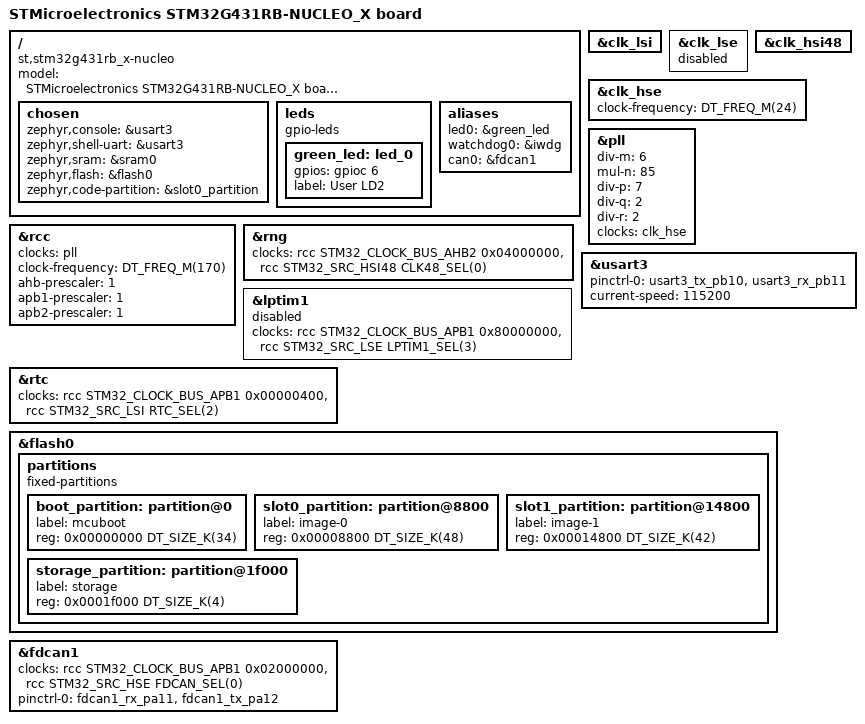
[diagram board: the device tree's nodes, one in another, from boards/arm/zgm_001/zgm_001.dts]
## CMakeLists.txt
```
# SPDX-License-Identifier: Apache-2.0

cmake_minimum_required(VERSION 3.20.0)

set(BOARD_ROOT ${CMAKE_CURRENT_SOURCE_DIR})
set(DTS_ROOT ${CMAKE_CURRENT_SOURCE_DIR})
set(DTC_OVERLAY_FILE ${CMAKE_CURRENT_SOURCE_DIR}/../modules/lib/motorlib/drivers/drivers@Eulre.0.1.overlay)

get_filename_component(MODULES_BASE_PATH "${CMAKE_CURRENT_SOURCE_DIR}/../modules/lib" ABSOLUTE)

# 添加Zephyr外部模块
list(APPEND ZEPHYR_EXTRA_MODULES
    "${MODULES_BASE_PATH}/motorlib"
    "${MODULES_BASE_PATH}/CommonLibrary"
    "${MODULES_BASE_PATH}/ProtocolV4"    
)


find_package(Zephyr REQUIRED HINTS $ENV{ZEPHYR_BASE})

project(euler)

# 添加源文件到 app target
target_sources(app PRIVATE
    src/main.c
    src/shell.c
)
```

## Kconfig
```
#motor / Kconfig
#必须包含 Zephyr 的主 Kconfig 以初始化核心配置
source "Kconfig.zephyr" 
```

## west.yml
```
manifest:
  self:
    path: Euler  # 修正拼写错误

  remotes:
    - name: github
      url-base: ssh://git@github.com 
    - name: origin 
      url-base: ssh://git@github.com/zagerx  # 改为 SSH 协议

  defaults:
    remote: origin
    revision: master
   
  projects:
    - name: zephyr
      remote: github
      repo-path: zephyrproject-rtos/zephyr
      revision: v4.1.0
      import: submanifests
      import:
        name-allowlist:
          - cmsis
          - cmsis-dsp
          - hal_stm32
          - segger
          - zcbor
          - canopennode
    - name: ProtocolV4
      path: modules/lib/ProtocolV4
      submodules: true
      revision: master

    - name: motorlib
      path: modules/lib/motorlib
      revision: master

    - name: CommonLibrary
      path: modules/lib/CommonLibrary
      revision: master

    - name: CustomMCUBoot
      path: bootloader/mcuboot
      remote: origin  # 改为存在的 remote
      revision: CustomMCUBoot

    - name: syrius-dts
      path: syrius-dts/
      remote: origin  # 改为存在的 remote
      revision: master
    
    - name: syrius-boards
      path: syrius-boards/
      remote: origin  # 改为存在的 remote
      revision: master
```

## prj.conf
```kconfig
CONFIG_GPIO=y
CONFIG_LOG=y
# 禁用 UART 控制台输出
CONFIG_UART_CONSOLE=y
CONFIG_UART_CONSOLE=y
CONFIG_SHELL=y
CONFIG_SHELL_BACKEND_SERIAL=y

# 启用 RTT 控制台
CONFIG_RTT_CONSOLE=n
CONFIG_TRACING=n
CONFIG_SEGGER_SYSTEMVIEW=n
CONFIG_USE_SEGGER_RTT=n

CONFIG_FPU=y
CONFIG_FPU_SHARING=y

#CONFIG_BOOTLOADER_MCUBOOT=y
#CONFIG_MCUBOOT_SIGNATURE_KEY_FILE="bootloader/mcuboot/root-rsa-2048.pem"
CONFIG_MOTORLIB_ENABLE=y
CONFIG_MOTOR_LIB_LOG_LEVEL=4
CONFIG_MOTOR_SUPER_ABZHALL_400W=n

CONFIG_ENCODER_TYPE_AS5047=y
CONFIG_SPI=y
CONFIG_USER_USE_STM32_HAL_SPI=y
CONFIG_USER_USE_STM32_HAL_ADC=y
CONFIG_USER_USE_STM32_HAL_TIM=y

CONFIG_MOTOR_DEBUG_MODE=y
CONFIG_MOTOR_DEBUG_ENCODERMODE=n
CONFIG_MOTOR_DEBUG_SELFLOOPMODE=y
CONFIG_MOTOR_DEBUG_TORQUE_PID=n
CONFIG_SPEEDLOOP_DEBUG=n
CONFIG_ABS_TYPE_ENCODER_CALIBRA=n
```

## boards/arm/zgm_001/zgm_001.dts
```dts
/*
 * Copyright (c) 2019 Richard Osterloh <richard.osterloh@gmail.com>
 *
 * SPDX-License-Identifier: Apache-2.0
 */

/dts-v1/;
#include <st/g4/stm32g431Xb.dtsi>
#include <st/g4/stm32g431c(6-8-b)ux-pinctrl.dtsi>

/ {
	model = "STMicroelectronics STM32G431RB-NUCLEO_X board";
	compatible = "st,stm32g431rb_x-nucleo";

	chosen {
		zephyr,console = &usart3;
		zephyr,shell-uart = &usart3;
		zephyr,sram = &sram0;
		zephyr,flash = &flash0;
		zephyr,code-partition = &slot0_partition;
	};

	leds: leds {
		compatible = "gpio-leds";
		green_led: led_0 {
			gpios = <&gpioc 6 GPIO_ACTIVE_HIGH>;
			label = "User LD2";
		};
	};
	aliases {
		led0 = &green_led;
		watchdog0 = &iwdg;
		can0 = &fdcan1;
	};
};

&clk_lsi {
	status = "okay";
};

&clk_lse {
	status = "disabled";
};

&clk_hsi48 {
	status = "okay";
};

&clk_hse {
	clock-frequency = <DT_FREQ_M(24)>;
	status = "okay";
};

&pll {
	div-m = <6>;
	mul-n = <85>;
	div-p = <7>;
	div-q = <2>;
	div-r = <2>;
	clocks = <&clk_hse>;
	status = "okay";
};

&rcc {
	clocks = <&pll>;
	clock-frequency = <DT_FREQ_M(170)>;
	ahb-prescaler = <1>;
	apb1-prescaler = <1>;
	apb2-prescaler = <1>;
};

&rng {
	clocks = <&rcc STM32_CLOCK_BUS_AHB2 0x04000000>,
		 <&rcc STM32_SRC_HSI48 CLK48_SEL(0)>;
	status = "okay";
};

&usart3 {
	pinctrl-0 = <&usart3_tx_pb10 &usart3_rx_pb11>;
	pinctrl-names = "default";
	current-speed = <115200>;
	status = "okay";
};

stm32_lp_tick_source: &lptim1 {
	clocks = <&rcc STM32_CLOCK_BUS_APB1 0x80000000>,
		 <&rcc STM32_SRC_LSE LPTIM1_SEL(3)>;
	status = "disabled";
};

&rtc {
	clocks = <&rcc STM32_CLOCK_BUS_APB1 0x00000400>,
		 <&rcc STM32_SRC_LSI RTC_SEL(2)>;
	status = "okay";
};

&flash0 {

	partitions {
		compatible = "fixed-partitions";
		#address-cells = <1>;
		#size-cells = <1>;

		boot_partition: partition@0 {
			label = "mcuboot";
			reg = <0x00000000 DT_SIZE_K(34)>;
		};
		slot0_partition: partition@8800 {
			label = "image-0";
			reg = <0x00008800 DT_SIZE_K(48)>;
		};
		slot1_partition: partition@14800 {
			label = "image-1";
			reg = <0x00014800 DT_SIZE_K(42)>;
		};
		/* Set 4Kb of storage at the end of the 128Kb of flash */
		storage_partition: partition@1f000 {
			label = "storage";
			reg = <0x0001f000 DT_SIZE_K(4)>;
		};
	};
};

/* 配置 CAN1 控制器 */
&fdcan1 {
	clocks = <&rcc STM32_CLOCK_BUS_APB1 0x02000000>,
	<&rcc STM32_SRC_HSE FDCAN_SEL(0)>;
	pinctrl-0 = <&fdcan1_rx_pa11 &fdcan1_tx_pa12>;
	pinctrl-names = "default";
	status = "okay";    
};
```

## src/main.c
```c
/*
 * Copyright (c) 2016 Intel Corporation
 *
 * SPDX-License-Identifier: Apache-2.0
 */

#include <zephyr/drivers/gpio.h>
#include <zephyr/kernel.h>
#include <zephyr/kernel.h>
#include "fault_monitoring_module.h"
#include "statemachine.h"
#include "zephyr/device.h"
#include <zephyr/drivers/gpio.h>
#include <zephyr/logging/log.h>
#include <lib/motor/motor.h>
#include <fault_monitoring_module.h>
#include <zephyr/sys/reboot.h>
/* 1000 msec = 1 sec */
#define LED0_NODE DT_ALIAS(led0)
const struct gpio_dt_spec led = GPIO_DT_SPEC_GET(LED0_NODE, gpios);

int main(void)
{
	const struct device *motor0 = DEVICE_DT_GET(DT_NODELABEL(motor0));
	const struct motor_data *m_data = motor0->data;
	gpio_pin_configure_dt(&led, GPIO_OUTPUT_ACTIVE); /* 先点亮 */

	int ret;
	// float bus_volcurur[2];
	// fmm_t *bus_vol_fmm = m_data->fault[0];
	// fmm_t *buf_curr_fmm = m_data->fault[1];
	// fmm_init(bus_vol_fmm, 60.0f, 48.0f, 5, 5, NULL);
	// fmm_init(buf_curr_fmm, 5.0f, 0.0f, 5, 5, NULL);

	// static int16_t fault_fsm = 0;
	static uint32_t conut = 0;
	k_msleep(200);
	while (1) {
		if (conut++ > 500) {
			conut = 0;
			gpio_pin_toggle_dt(&led);
		}
		// motor_get_bus_voltage_current(motor0, &bus_volcurur[0], &bus_volcurur[1]);
		// motor_set_vol(motor0, bus_volcurur);

		// fmm_monitoring(bus_vol_fmm, bus_volcurur[0]);
		// fmm_monitoring(buf_curr_fmm, bus_volcurur[1]);

		DISPATCH_FSM(m_data->mode_state_mec);

		k_msleep(1);
	}
	return ret;
}
```

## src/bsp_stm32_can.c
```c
#include <string.h>
#include <zephyr/device.h>
#include <zephyr/drivers/can.h>
#include <zephyr/kernel.h>
#include <zephyr/logging/log.h>
#include <zephyr/sys/printk.h>
LOG_MODULE_REGISTER(stm32_can, LOG_LEVEL_DBG);

const struct device *const can_dev = DEVICE_DT_GET(DT_NODELABEL(fdcan1));

// 前置声明
static void can_rx_callback(const struct device *dev, struct can_frame *frame, void *user_data);

int can_init(void)
{
	if (!device_is_ready(can_dev)) {
		LOG_INF("dev no ready");
		return -ENODEV;
	}
	// 停止 CAN 设备
	can_stop(can_dev);
	k_msleep(100); // 等待设备完全停止

	struct can_timing timing;
	int ret = can_calc_timing(can_dev, &timing, 1000000, 875); // 10kbps, 87.5%采样点
	if (ret < 0) {
		return ret;
	}

	ret = can_set_timing(can_dev, &timing);
	if (ret < 0) {
		return ret;
	}

	// 设置模式前确保控制器就绪
	while (can_set_mode(can_dev, CAN_MODE_NORMAL) == -EBUSY) {
		k_msleep(1);
	}

	// LOG_INF("can init finish");

	struct can_filter filter = {
		.id = 0x00000000,   // 匹配所有标准ID
		.mask = 0x00000000, // 掩码全0表示不检查任何位
		.flags = 0          // 明确指定标准帧
	};
	int filter_id = can_add_rx_filter(can_dev, can_rx_callback, NULL, &filter);
	LOG_INF("Added filter %d (id=0x%x mask=0x%x)", filter_id, filter.id, filter.mask);

	// 打印硬件状态
	uint32_t core_clock;
	can_get_core_clock(can_dev, &core_clock);
	LOG_INF("CAN core clock: %u Hz", core_clock);

	can_start(can_dev);
	return 0;
}
K_MSGQ_DEFINE(rx_msgq, sizeof(struct can_frame), 10, 4);

static void can_rx_callback(const struct device *dev, struct can_frame *frame, void *user_data)
{
	//   k_msgq_put(&rx_msgq, frame, K_NO_WAIT); // 非阻塞入队
	LOG_INF("RX ID:%03x DLC:%d Data:", frame->id, frame->dlc);
	for (int i = 0; i < frame->dlc; i++) {
		LOG_INF("%02x ", frame->data[i]);
	}
	LOG_INF("");
}
```

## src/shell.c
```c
#include <zephyr/kernel.h>
#include <zephyr/shell/shell.h>
#include <stdlib.h>
#include <zephyr/drivers/gpio.h>

#include "lib/motor/motor.h"
#include "zephyr/posix/sys/stat.h"
const struct device *motor = DEVICE_DT_GET(DT_NODELABEL(motor0));

static int cmd_hello(const struct shell *sh, size_t argc, char **argv)
{
	ARG_UNUSED(argc);
	ARG_UNUSED(argv);

	shell_print(sh, "Hello Zephyr Shell! argc=%d", argc);
	return 0;
}

static int cmd_motor_set_ready(const struct shell *sh, size_t argc, char **argv)
{
	ARG_UNUSED(argc);
	ARG_UNUSED(argv);
	motor_set_state(motor, MOTOR_STATE_READY);
	return 0;
}
// static int cmd_motor_set_aligh(const struct shell *sh, size_t argc, char **argv)
// {
// 	ARG_UNUSED(argc);
// 	ARG_UNUSED(argv);
// 	motor_set_state(motor, MOTOR_STATE_ALIGN);
// 	return 0;
// }
static int cmd_motor_set_disable(const struct shell *sh, size_t argc, char **argv)
{
	ARG_UNUSED(argc);
	ARG_UNUSED(argv);
	motor_set_state(motor, MOTOR_STATE_STOP);
	return 0;
}
static int cmd_motor_set_closeloop(const struct shell *sh, size_t argc, char **argv)
{
	ARG_UNUSED(argc);
	ARG_UNUSED(argv);
	motor_set_state(motor, MOTOR_STATE_CLOSED_LOOP);
	return 0;
}
static int cmd_motor_set_speed(const struct shell *sh, size_t argc, char **argv)
{
	if (argc != 2) {
		shell_error(sh, "Usage: add <num1> <num2>");
		return -EINVAL;
	}
	long temp = strtol(argv[1], NULL, 0);
	float speed = (float)temp / 1000.0f;
	motor_set_target_speed(motor, speed);
	motor_set_state(motor, MOTOR_STATE_CLOSED_LOOP);
	return 0;
}

static int cmd_motor_set_mode(const struct shell *sh, size_t argc, char **argv)
{
	if (argc != 2) {
		shell_error(sh, "Usage: add <num1> <num2>");
		return -EINVAL;
	}
	long mode = strtol(argv[1], NULL, 0);
	if (mode == 1) {
		motor_set_mode(motor, MOTOR_MODE_SPEED);
	} else if (mode == 2) {
		motor_set_mode(motor, MOTOR_MODE_POSI);
	} else if (mode == 3) {
		motor_set_mode(motor, MOTOR_MODE_TORQUE);
	} else if (mode == 5) {
		motor_set_mode(motor, MOTOR_MODE_IDLE);
	}
	return 0;
}
static int cmd_motor_set_toque(const struct shell *sh, size_t argc, char **argv)
{
	if (argc != 3) {
		shell_error(sh, "Usage: add <num1> <num2>");
		return -EINVAL;
	}
	long d_ref = strtol(argv[1], NULL, 0);
	long q_ref = strtol(argv[2], NULL, 0);
	float d_ref_float = (float)d_ref / 1000.0f;
	float q_ref_float = (float)q_ref / 1000.0f;
	motor_set_torque(motor, d_ref_float, q_ref_float);
	motor_set_state(motor, MOTOR_STATE_CLOSED_LOOP);
	return 0;
}

static int cmd_motor_set_posi(const struct shell *sh, size_t argc, char **argv)
{
	if (argc != 2) {
		shell_error(sh, "Usage: add <num1> <num2>");
		return -EINVAL;
	}
	long mode = strtol(argv[1], NULL, 0);
	if (mode == 1) {
		motor_clear_realodom(motor, 0.0f);
		motor_set_target_position(motor, 0.0f, -1500.0f, 5.0f);
	} else if (mode == 2) {
		motor_set_target_position(motor, -1500.0f, 0.0f, 5.0f);
	}
	motor_set_state(motor, MOTOR_STATE_CLOSED_LOOP);
	return 0;
}
static int cmd_motor_get_modestate(const struct shell *sh, size_t argc, char **argv)
{
	if (argc != 2) {
		shell_error(sh, "Usage: add <num1> <num2>");
		return -EINVAL;
	}
	long state = strtol(argv[1], NULL, 0);
	if (state == 1) {
		if (motor_get_state(motor) == MOTOR_STATE_READY) {
			shell_print(sh, "motor_ready_state");
		} else if (motor_get_state(motor) == MOTOR_STATE_CLOSED_LOOP) {
			shell_print(sh, "motor_runing_state");
		} else if (motor_get_state(motor) == MOTOR_STATE_STOP) {
			shell_print(sh, "motor_stop_state");
		} else if (motor_get_state(motor) == MOTOR_STATE_IDLE) {
			shell_print(sh, "motor_idle_state");
		} else if (motor_get_state(motor) == MOTOR_STATE_FAULT) {
			shell_print(sh, " motor_falut_state");
		} else if (motor_get_state(motor) == MOTOR_STATE_ALIGN) {
			shell_print(sh, " motor_aligh_state");
		}
	} else if (state == 2) {
		if (motor_get_mode(motor) == MOTOR_MODE_TORQUE) {
			shell_print(sh, " motor_torque_control_mode");
		} else if (motor_get_mode(motor) == MOTOR_MODE_SPEED) {
			shell_print(sh, "motor_speed_control_mode");
		} else if (motor_get_mode(motor) == MOTOR_MODE_POSI) {
			shell_print(sh, "motor_position_control_mode");
		}
	}
	return 0;
}
SHELL_CMD_REGISTER(hello, NULL, "Print hello", cmd_hello);
SHELL_CMD_REGISTER(mode, NULL, "Motor Set Mode", cmd_motor_set_mode);
SHELL_CMD_REGISTER(r, NULL, "Motor Set Ready", cmd_motor_set_ready);
// SHELL_CMD_REGISTER(a, NULL, "Motor Set Close", cmd_motor_set_aligh);
SHELL_CMD_REGISTER(c, NULL, "Motor Set Close", cmd_motor_set_closeloop);
SHELL_CMD_REGISTER(speed, NULL, "Motor Set Speed", cmd_motor_set_speed);
SHELL_CMD_REGISTER(s, NULL, "Motor Set Stop", cmd_motor_set_disable);
SHELL_CMD_REGISTER(p, NULL, "Motor Set Posi", cmd_motor_set_posi);
SHELL_CMD_REGISTER(t, NULL, "Motor Set Toque", cmd_motor_set_toque);
SHELL_CMD_REGISTER(g, NULL, "Motor Get State", cmd_motor_get_modestate);
```
